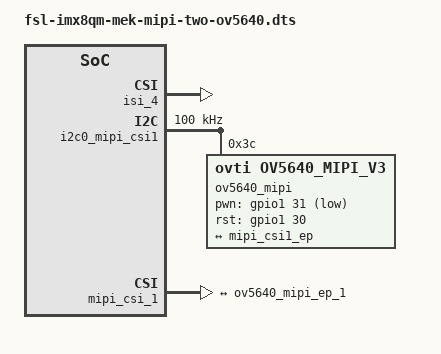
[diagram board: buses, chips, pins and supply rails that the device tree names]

/*
 * Copyright 2018 NXP
 *
 * This program is free software; you can redistribute it and/or
 * modify it under the terms of the GNU General Public License
 * as published by the Free Software Foundation; either version 2
 * of the License, or (at your option) any later version.
 *
 * This program is distributed in the hope that it will be useful,
 * but WITHOUT ANY WARRANTY; without even the implied warranty of
 * MERCHANTABILITY or FITNESS FOR A PARTICULAR PURPOSE.  See the
 * GNU General Public License for more details.
 */

#include "fsl-imx8qm-mek-mipi-ov5640.dts"

&iomuxc {
	imx8qm-mek {
		pinctrl_mipi_csi1: mipicsi1grp{
			fsl,pins = <
				SC_P_MIPI_CSI1_MCLK_OUT_MIPI_CSI1_ACM_MCLK_OUT	0xC0000041
			>;
		};
	};
};

&isi_4 {
	status = "okay";
};

&i2c0_mipi_csi1 {
	clock-frequency = <100000>;
	status = "okay";

	ov5640_mipi@3c {
		compatible = "ovti,ov5640_mipi_v3";
		reg = <0x3c>;
		pinctrl-names = "default";
		pinctrl-0 = <&pinctrl_mipi_csi1>;
		clocks = <&clk IMX8QM_CLK_DUMMY>;
		clock-names = "csi_mclk";
		csi_id = <1>;
		pwn-gpios = <&gpio1 31 GPIO_ACTIVE_LOW>;
		rst-gpios = <&gpio1 30 GPIO_ACTIVE_HIGH>;
		mclk = <24000000>;
		mclk_source = <0>;
		mipi_csi;
		status = "okay";
		port {
			ov5640_mipi_ep_1: endpoint {
				remote-endpoint = <&mipi_csi1_ep>;
			};
		};
	};

	max9286_mipi@6A {
		status = "disabled";
	};
};

&mipi_csi_1 {
	/delete-property/virtual-channel;
	status = "okay";

	port@1 {
		reg = <1>;
		mipi_csi1_ep: endpoint {
			remote-endpoint = <&ov5640_mipi_ep_1>;
			data-lanes = <1 2>;
		};
	};
};
